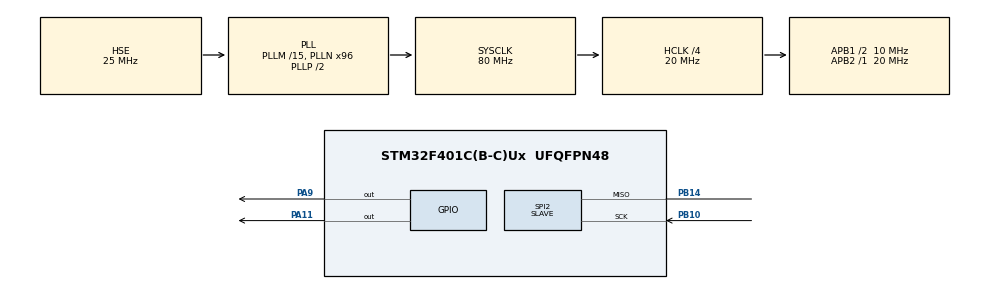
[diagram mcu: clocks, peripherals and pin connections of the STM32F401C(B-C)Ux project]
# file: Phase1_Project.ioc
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Dma.Request0=SPI2_TX
Dma.Request1=SPI2_RX
Dma.SPI2_RX.1.Direction=DMA_PERIPH_TO_MEMORY
Dma.SPI2_RX.1.FIFOMode=DMA_FIFOMODE_DISABLE
Dma.SPI2_RX.1.Instance=DMA1_Stream3
Dma.SPI2_RX.1.MemDataAlignment=DMA_MDATAALIGN_HALFWORD
Dma.SPI2_RX.1.MemInc=DMA_MINC_ENABLE
Dma.SPI2_RX.1.Mode=DMA_NORMAL
Dma.SPI2_RX.1.PeriphDataAlignment=DMA_PDATAALIGN_HALFWORD
Dma.SPI2_RX.1.PeriphInc=DMA_PINC_DISABLE
Dma.SPI2_RX.1.Priority=DMA_PRIORITY_LOW
Dma.SPI2_TX.0.Direction=DMA_MEMORY_TO_PERIPH
Dma.SPI2_TX.0.FIFOMode=DMA_FIFOMODE_DISABLE
Dma.SPI2_TX.0.Instance=DMA1_Stream4
Dma.SPI2_TX.0.MemDataAlignment=DMA_MDATAALIGN_HALFWORD
Dma.SPI2_TX.0.MemInc=DMA_MINC_ENABLE
Dma.SPI2_TX.0.Mode=DMA_NORMAL
Dma.SPI2_TX.0.PeriphDataAlignment=DMA_PDATAALIGN_HALFWORD
Dma.SPI2_TX.0.PeriphInc=DMA_PINC_DISABLE
Dma.SPI2_TX.0.Priority=DMA_PRIORITY_LOW
Mcu.Family=STM32F4
Mcu.Name=STM32F401C(B-C)Ux
Mcu.Package=UFQFPN48
NVIC.DMA1_Stream3_IRQn=true\:0\:0\:false\:false\:true\:false\:true\:true
NVIC.DMA1_Stream4_IRQn=true\:0\:0\:false\:false\:true\:false\:true\:true
NVIC.PriorityGroup=NVIC_PRIORITYGROUP_4
NVIC.RCC_IRQn=true\:0\:0\:false\:false\:true\:true\:false\:true
PA11.Signal=GPIO_Output
PA9.Signal=GPIO_Output
PB10.Mode=Simplex_Bidirectional_Slave
PB10.Signal=SPI2_SCK
PB14.Mode=Simplex_Bidirectional_Slave
PB14.Signal=SPI2_MISO
PB15.GPIO_Speed=GPIO_SPEED_FREQ_HIGH
PB15.Signal=SPI2_MOSI
PH0\ -\ OSC_IN.Mode=HSE-External-Oscillator
PH0\ -\ OSC_IN.Signal=RCC_OSC_IN
PH1\ -\ OSC_OUT.Mode=HSE-External-Oscillator
PH1\ -\ OSC_OUT.Signal=RCC_OSC_OUT
ProjectManager.HeapSize=0x200
ProjectManager.StackSize=0x400
ProjectManager.TargetToolchain=STM32CubeIDE
RCC.48MHZClocksFreq_Value=40000000
RCC.AHBCLKDivider=RCC_SYSCLK_DIV4
RCC.AHBFreq_Value=20000000
RCC.APB1CLKDivider=RCC_HCLK_DIV2
RCC.APB1Freq_Value=10000000
RCC.APB1TimFreq_Value=20000000
RCC.APB2Freq_Value=20000000
RCC.APB2TimFreq_Value=20000000
RCC.CortexFreq_Value=20000000
RCC.HCLKFreq_Value=20000000
RCC.HSE_VALUE=25000000
RCC.HSI_VALUE=16000000
RCC.LSE_VALUE=32768
RCC.PLLM=15
RCC.PLLN=96
RCC.PLLSourceVirtual=RCC_PLLSOURCE_HSE
RCC.SYSCLKFreq_VALUE=80000000
RCC.SYSCLKSource=RCC_SYSCLKSOURCE_PLLCLK
RCC.VCOOutputFreq_Value=160000000
SPI2.CRCCalculation=SPI_CRCCALCULATION_ENABLE
SPI2.DataSize=SPI_DATASIZE_16BIT
SPI2.Direction=SPI_DIRECTION_1LINE
SPI2.Mode=SPI_MODE_SLAVE
SPI2.VirtualType=VM_SLAVE
TIM3.Channel-PWM\ Generation3\ No\ Output=TIM_CHANNEL_3
TIM3.Channel-PWM\ Generation4\ No\ Output=TIM_CHANNEL_4
VP_CRC_VS_CRC.Mode=CRC_Activate
VP_IWDG_VS_IWDG.Mode=IWDG_Activate
VP_TIM3_VS_no_output3.Mode=PWM Generation3 No Output
VP_TIM3_VS_no_output4.Mode=PWM Generation4 No Output
VP_WWDG_VS_WWDG.Mode=WWDG_Activate
board=custom

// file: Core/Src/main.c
/* USER CODE BEGIN Header */
/**
  ******************************************************************************
  * @file           : main.c
  * @brief          : Main program body
  ******************************************************************************
  * @attention
  *
  * Copyright (c) 2023 STMicroelectronics.
  * All rights reserved.
  *
  * This software is licensed under terms that can be found in the LICENSE file
  * in the root directory of this software component.
  * If no LICENSE file comes with this software, it is provided AS-IS.
  *
  ******************************************************************************
  */
/* USER CODE END Header */
#include "main.h"
#include "crc.h"
#include "dma.h"
#include "iwdg.h"
#include "spi.h"
#include "tim.h"
#include "wwdg.h"
#include "gpio.h"

void SystemClock_Config(void);

/* USER CODE BEGIN 0 */
uint8_t txData[2];
 uint8_t rxData;
/* USER CODE END 0 */

int main(void)
{

  /* MCU Configuration--------------------------------------------------------*/

  /* Reset of all peripherals, Initializes the Flash interface and the Systick. */
  HAL_Init();

  /* Configure the system clock */
  SystemClock_Config();

  /* Initialize all configured peripherals */
  MX_GPIO_Init();
  MX_DMA_Init();
  MX_CRC_Init();
  MX_SPI2_Init();
  MX_TIM3_Init();
  MX_IWDG_Init();
  MX_WWDG_Init();

  /* Infinite loop */
  /* USER CODE BEGIN WHILE */
  while (1)
  {
	  HAL_GPIO_WritePin(GPIOA, GPIO_PIN_11, GPIO_PIN_SET);
	  HAL_Delay(500);
	  HAL_GPIO_WritePin(GPIOA, GPIO_PIN_11, GPIO_PIN_RESET);
	  HAL_Delay(500);

    /* USER CODE END WHILE */

  }
}

void SystemClock_Config(void)
{
  RCC_OscInitTypeDef RCC_OscInitStruct = {0};
  RCC_ClkInitTypeDef RCC_ClkInitStruct = {0};

  /** Configure the main internal regulator output voltage
  */
  __HAL_RCC_PWR_CLK_ENABLE();
  __HAL_PWR_VOLTAGESCALING_CONFIG(PWR_REGULATOR_VOLTAGE_SCALE2);

  /** Initializes the RCC Oscillators according to the specified parameters
  * in the RCC_OscInitTypeDef structure.
  */
  RCC_OscInitStruct.OscillatorType = RCC_OSCILLATORTYPE_LSI|RCC_OSCILLATORTYPE_HSE;
  RCC_OscInitStruct.HSEState = RCC_HSE_ON;
  RCC_OscInitStruct.LSIState = RCC_LSI_ON;
  RCC_OscInitStruct.PLL.PLLState = RCC_PLL_ON;
  RCC_OscInitStruct.PLL.PLLSource = RCC_PLLSOURCE_HSE;
  RCC_OscInitStruct.PLL.PLLM = 15;
  RCC_OscInitStruct.PLL.PLLN = 96;
  RCC_OscInitStruct.PLL.PLLP = RCC_PLLP_DIV2;
  RCC_OscInitStruct.PLL.PLLQ = 4;
  if (HAL_RCC_OscConfig(&RCC_OscInitStruct) != HAL_OK)
  {
    Error_Handler();
  }

  /** Initializes the CPU, AHB and APB buses clocks
  */
  RCC_ClkInitStruct.ClockType = RCC_CLOCKTYPE_HCLK|RCC_CLOCKTYPE_SYSCLK
                              |RCC_CLOCKTYPE_PCLK1|RCC_CLOCKTYPE_PCLK2;
  RCC_ClkInitStruct.SYSCLKSource = RCC_SYSCLKSOURCE_PLLCLK;
  RCC_ClkInitStruct.AHBCLKDivider = RCC_SYSCLK_DIV4;
  RCC_ClkInitStruct.APB1CLKDivider = RCC_HCLK_DIV2;
  RCC_ClkInitStruct.APB2CLKDivider = RCC_HCLK_DIV1;

  if (HAL_RCC_ClockConfig(&RCC_ClkInitStruct, FLASH_LATENCY_0) != HAL_OK)
  {
    Error_Handler();
  }
}

void Error_Handler(void)
{
  __disable_irq();
  while (1)
  {
  }
}
